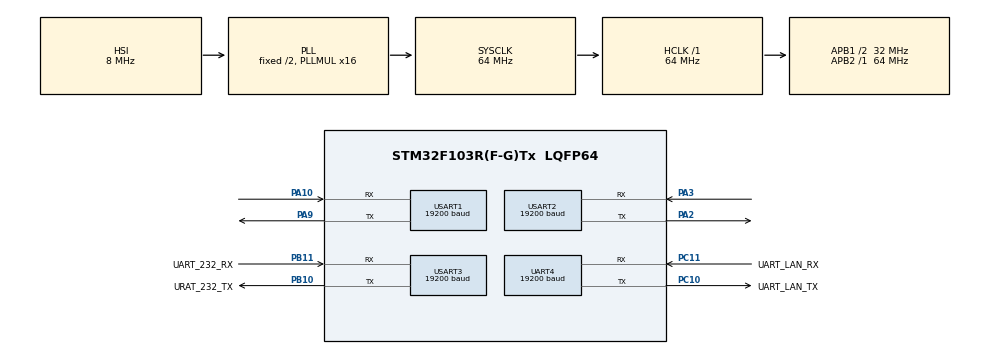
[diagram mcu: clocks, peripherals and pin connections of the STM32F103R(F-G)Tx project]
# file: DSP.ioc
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Dma.Request0=USART3_RX
Dma.Request1=UART4_RX
Dma.Request2=UART4_TX
Dma.Request3=USART3_TX
Dma.Request4=USART1_RX
Dma.Request5=USART1_TX
Dma.Request6=USART2_RX
Dma.Request7=USART2_TX
Dma.UART4_RX.1.Direction=DMA_PERIPH_TO_MEMORY
Dma.UART4_RX.1.Instance=DMA2_Channel3
Dma.UART4_RX.1.MemDataAlignment=DMA_MDATAALIGN_BYTE
Dma.UART4_RX.1.MemInc=DMA_MINC_ENABLE
Dma.UART4_RX.1.Mode=DMA_NORMAL
Dma.UART4_RX.1.PeriphDataAlignment=DMA_PDATAALIGN_BYTE
Dma.UART4_RX.1.PeriphInc=DMA_PINC_DISABLE
Dma.UART4_RX.1.Priority=DMA_PRIORITY_LOW
Dma.UART4_TX.2.Direction=DMA_MEMORY_TO_PERIPH
Dma.UART4_TX.2.Instance=DMA2_Channel5
Dma.UART4_TX.2.MemDataAlignment=DMA_MDATAALIGN_BYTE
Dma.UART4_TX.2.MemInc=DMA_MINC_ENABLE
Dma.UART4_TX.2.Mode=DMA_NORMAL
Dma.UART4_TX.2.PeriphDataAlignment=DMA_PDATAALIGN_BYTE
Dma.UART4_TX.2.PeriphInc=DMA_PINC_DISABLE
Dma.UART4_TX.2.Priority=DMA_PRIORITY_LOW
Dma.USART1_RX.4.Direction=DMA_PERIPH_TO_MEMORY
Dma.USART1_RX.4.Instance=DMA1_Channel5
Dma.USART1_RX.4.MemDataAlignment=DMA_MDATAALIGN_BYTE
Dma.USART1_RX.4.MemInc=DMA_MINC_ENABLE
Dma.USART1_RX.4.Mode=DMA_NORMAL
Dma.USART1_RX.4.PeriphDataAlignment=DMA_PDATAALIGN_BYTE
Dma.USART1_RX.4.PeriphInc=DMA_PINC_DISABLE
Dma.USART1_RX.4.Priority=DMA_PRIORITY_LOW
Dma.USART1_TX.5.Direction=DMA_MEMORY_TO_PERIPH
Dma.USART1_TX.5.Instance=DMA1_Channel4
Dma.USART1_TX.5.MemDataAlignment=DMA_MDATAALIGN_BYTE
Dma.USART1_TX.5.MemInc=DMA_MINC_ENABLE
Dma.USART1_TX.5.Mode=DMA_NORMAL
Dma.USART1_TX.5.PeriphDataAlignment=DMA_PDATAALIGN_BYTE
Dma.USART1_TX.5.PeriphInc=DMA_PINC_DISABLE
Dma.USART1_TX.5.Priority=DMA_PRIORITY_LOW
Dma.USART2_RX.6.Direction=DMA_PERIPH_TO_MEMORY
Dma.USART2_RX.6.Instance=DMA1_Channel6
Dma.USART2_RX.6.MemDataAlignment=DMA_MDATAALIGN_BYTE
Dma.USART2_RX.6.MemInc=DMA_MINC_ENABLE
Dma.USART2_RX.6.Mode=DMA_NORMAL
Dma.USART2_RX.6.PeriphDataAlignment=DMA_PDATAALIGN_BYTE
Dma.USART2_RX.6.PeriphInc=DMA_PINC_DISABLE
Dma.USART2_RX.6.Priority=DMA_PRIORITY_LOW
Dma.USART2_TX.7.Direction=DMA_MEMORY_TO_PERIPH
Dma.USART2_TX.7.Instance=DMA1_Channel7
Dma.USART2_TX.7.MemDataAlignment=DMA_MDATAALIGN_BYTE
Dma.USART2_TX.7.MemInc=DMA_MINC_ENABLE
Dma.USART2_TX.7.Mode=DMA_NORMAL
Dma.USART2_TX.7.PeriphDataAlignment=DMA_PDATAALIGN_BYTE
Dma.USART2_TX.7.PeriphInc=DMA_PINC_DISABLE
Dma.USART2_TX.7.Priority=DMA_PRIORITY_LOW
Dma.USART3_RX.0.Direction=DMA_PERIPH_TO_MEMORY
Dma.USART3_RX.0.Instance=DMA1_Channel3
Dma.USART3_RX.0.MemDataAlignment=DMA_MDATAALIGN_BYTE
Dma.USART3_RX.0.MemInc=DMA_MINC_ENABLE
Dma.USART3_RX.0.Mode=DMA_NORMAL
Dma.USART3_RX.0.PeriphDataAlignment=DMA_PDATAALIGN_BYTE
Dma.USART3_RX.0.PeriphInc=DMA_PINC_DISABLE
Dma.USART3_RX.0.Priority=DMA_PRIORITY_LOW
Dma.USART3_TX.3.Direction=DMA_MEMORY_TO_PERIPH
Dma.USART3_TX.3.Instance=DMA1_Channel2
Dma.USART3_TX.3.MemDataAlignment=DMA_MDATAALIGN_BYTE
Dma.USART3_TX.3.MemInc=DMA_MINC_ENABLE
Dma.USART3_TX.3.Mode=DMA_NORMAL
Dma.USART3_TX.3.PeriphDataAlignment=DMA_PDATAALIGN_BYTE
Dma.USART3_TX.3.PeriphInc=DMA_PINC_DISABLE
Dma.USART3_TX.3.Priority=DMA_PRIORITY_LOW
Mcu.Family=STM32F1
Mcu.Name=STM32F103R(F-G)Tx
Mcu.Package=LQFP64
NVIC.DMA1_Channel2_IRQn=true\:0\:0\:false\:false\:true\:false\:true\:true
NVIC.DMA1_Channel3_IRQn=true\:0\:0\:false\:false\:true\:false\:true\:true
NVIC.DMA1_Channel4_IRQn=true\:0\:0\:false\:false\:true\:false\:true\:true
NVIC.DMA1_Channel5_IRQn=true\:0\:0\:false\:false\:true\:false\:true\:true
NVIC.DMA1_Channel6_IRQn=true\:0\:0\:false\:false\:true\:false\:true\:true
NVIC.DMA1_Channel7_IRQn=true\:0\:0\:false\:false\:true\:false\:true\:true
NVIC.DMA2_Channel3_IRQn=true\:0\:0\:false\:false\:true\:false\:true\:true
NVIC.DMA2_Channel4_5_IRQn=true\:0\:0\:false\:false\:true\:false\:true\:true
NVIC.PriorityGroup=NVIC_PRIORITYGROUP_4
NVIC.UART4_IRQn=true\:0\:0\:false\:false\:true\:true\:true\:true
NVIC.USART1_IRQn=true\:0\:0\:false\:false\:true\:true\:true\:true
NVIC.USART2_IRQn=true\:0\:0\:false\:false\:true\:true\:true\:true
NVIC.USART3_IRQn=true\:0\:0\:false\:false\:true\:true\:true\:true
PA10.Mode=Asynchronous
PA10.Signal=USART1_RX
PA13.Mode=Serial_Wire
PA13.Signal=SYS_JTMS-SWDIO
PA14.Mode=Serial_Wire
PA14.Signal=SYS_JTCK-SWCLK
PA2.Mode=Asynchronous
PA2.Signal=USART2_TX
PA3.Mode=Asynchronous
PA3.Signal=USART2_RX
PA9.Mode=Asynchronous
PA9.Signal=USART1_TX
PB10.GPIO_Label=URAT_232_TX
PB10.Mode=Asynchronous
PB10.Signal=USART3_TX
PB11.GPIO_Label=UART_232_RX
PB11.Mode=Asynchronous
PB11.Signal=USART3_RX
PC10.GPIO_Label=UART_LAN_TX
PC10.Mode=Asynchronous
PC10.Signal=UART4_TX
PC11.GPIO_Label=UART_LAN_RX
PC11.Mode=Asynchronous
PC11.Signal=UART4_RX
ProjectManager.HeapSize=0x200
ProjectManager.StackSize=0x400
ProjectManager.TargetToolchain=MDK-ARM V5.32
RCC.AHBFreq_Value=64000000
RCC.APB1CLKDivider=RCC_HCLK_DIV2
RCC.APB1Freq_Value=32000000
RCC.APB1TimFreq_Value=64000000
RCC.APB2Freq_Value=64000000
RCC.APB2TimFreq_Value=64000000
RCC.HCLKFreq_Value=64000000
RCC.PLLMUL=RCC_PLL_MUL16
RCC.SYSCLKFreq_VALUE=64000000
RCC.SYSCLKSource=RCC_SYSCLKSOURCE_PLLCLK
RCC.USBFreq_Value=64000000
UART4.BaudRate=19200
UART4.VirtualMode=Asynchronous
USART1.BaudRate=19200
USART1.VirtualMode=VM_ASYNC
USART2.BaudRate=19200
USART2.VirtualMode=VM_ASYNC
USART3.BaudRate=19200
USART3.VirtualMode=VM_ASYNC
board=custom

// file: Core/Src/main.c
/* USER CODE BEGIN Header */
/**
  ******************************************************************************
  * @file           : main.c
  * @brief          : Main program body
  ******************************************************************************
  * @attention
  *
  * Copyright (c) 2022 STMicroelectronics.
  * All rights reserved.
  *
  * This software is licensed under terms that can be found in the LICENSE file
  * in the root directory of this software component.
  * If no LICENSE file comes with this software, it is provided AS-IS.
  *
  ******************************************************************************
  */
/* USER CODE END Header */
#include "main.h"
#include "dma.h"
#include "usart.h"
#include "gpio.h"

/* USER CODE BEGIN Includes */
#include "bootloader.h"

/* USER CODE END Includes */

void SystemClock_Config(void);

int main(void)
{

  /* MCU Configuration--------------------------------------------------------*/

  /* Reset of all peripherals, Initializes the Flash interface and the Systick. */
  HAL_Init();

  /* Configure the system clock */
  SystemClock_Config();

  /* Initialize all configured peripherals */
  MX_GPIO_Init();
  MX_DMA_Init();
  MX_USART3_UART_Init();
  MX_UART4_Init();
  MX_USART1_UART_Init();
  MX_USART2_UART_Init();
  /* USER CODE BEGIN 2 */
	boot_uart_config();
	poweron_self_check();
  /* USER CODE END 2 */

  /* Infinite loop */
  /* USER CODE BEGIN WHILE */
  while (1)
  {
	bsp_ota_handle();
    /* USER CODE END WHILE */

  }
}

void SystemClock_Config(void)
{
  RCC_OscInitTypeDef RCC_OscInitStruct = {0};
  RCC_ClkInitTypeDef RCC_ClkInitStruct = {0};

  /** Initializes the RCC Oscillators according to the specified parameters
  * in the RCC_OscInitTypeDef structure.
  */
  RCC_OscInitStruct.OscillatorType = RCC_OSCILLATORTYPE_HSI;
  RCC_OscInitStruct.HSIState = RCC_HSI_ON;
  RCC_OscInitStruct.HSICalibrationValue = RCC_HSICALIBRATION_DEFAULT;
  RCC_OscInitStruct.PLL.PLLState = RCC_PLL_ON;
  RCC_OscInitStruct.PLL.PLLSource = RCC_PLLSOURCE_HSI_DIV2;
  RCC_OscInitStruct.PLL.PLLMUL = RCC_PLL_MUL16;
  if (HAL_RCC_OscConfig(&RCC_OscInitStruct) != HAL_OK)
  {
    Error_Handler();
  }

  /** Initializes the CPU, AHB and APB buses clocks
  */
  RCC_ClkInitStruct.ClockType = RCC_CLOCKTYPE_HCLK|RCC_CLOCKTYPE_SYSCLK
                              |RCC_CLOCKTYPE_PCLK1|RCC_CLOCKTYPE_PCLK2;
  RCC_ClkInitStruct.SYSCLKSource = RCC_SYSCLKSOURCE_PLLCLK;
  RCC_ClkInitStruct.AHBCLKDivider = RCC_SYSCLK_DIV1;
  RCC_ClkInitStruct.APB1CLKDivider = RCC_HCLK_DIV2;
  RCC_ClkInitStruct.APB2CLKDivider = RCC_HCLK_DIV1;

  if (HAL_RCC_ClockConfig(&RCC_ClkInitStruct, FLASH_LATENCY_2) != HAL_OK)
  {
    Error_Handler();
  }
}

void Error_Handler(void)
{
  __disable_irq();
  while (1)
  {
  }
}
